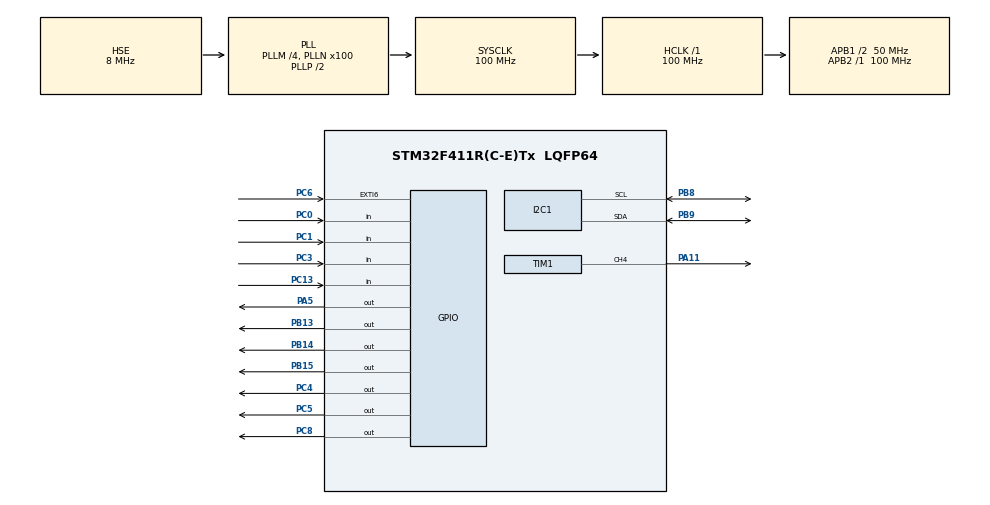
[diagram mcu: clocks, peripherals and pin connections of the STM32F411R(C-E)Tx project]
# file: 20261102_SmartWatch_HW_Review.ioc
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Mcu.Family=STM32F4
Mcu.Name=STM32F411R(C-E)Tx
Mcu.Package=LQFP64
NVIC.EXTI9_5_IRQn=true\:0\:0\:false\:false\:true\:false\:true\:true
NVIC.PriorityGroup=NVIC_PRIORITYGROUP_4
PA11.Signal=S_TIM1_CH4
PA13.Mode=Serial_Wire
PA13.Signal=SYS_JTMS-SWDIO
PA14.Mode=Serial_Wire
PA14.Signal=SYS_JTCK-SWCLK
PA5.Signal=GPIO_Output
PB13.Signal=GPIO_Output
PB14.Signal=GPIO_Output
PB15.Signal=GPIO_Output
PB8.Mode=I2C
PB8.Signal=I2C1_SCL
PB9.Mode=I2C
PB9.Signal=I2C1_SDA
PC0.Signal=GPIO_Input
PC1.Signal=GPIO_Input
PC13-ANTI_TAMP.Signal=GPIO_Input
PC3.Signal=GPIO_Input
PC4.Signal=GPIO_Output
PC5.Signal=GPIO_Output
PC6.GPIO_ModeDefaultEXTI=GPIO_MODE_IT_RISING_FALLING
PC6.Signal=GPXTI6
PC8.Signal=GPIO_Output
PH0\ -\ OSC_IN.Mode=HSE-External-Oscillator
PH0\ -\ OSC_IN.Signal=RCC_OSC_IN
PH1\ -\ OSC_OUT.Mode=HSE-External-Oscillator
PH1\ -\ OSC_OUT.Signal=RCC_OSC_OUT
ProjectManager.HeapSize=0x200
ProjectManager.StackSize=0x400
ProjectManager.TargetToolchain=STM32CubeIDE
RCC.48MHZClocksFreq_Value=50000000
RCC.AHBFreq_Value=100000000
RCC.APB1CLKDivider=RCC_HCLK_DIV2
RCC.APB1Freq_Value=50000000
RCC.APB1TimFreq_Value=100000000
RCC.APB2Freq_Value=100000000
RCC.APB2TimFreq_Value=100000000
RCC.CortexFreq_Value=100000000
RCC.HCLKFreq_Value=100000000
RCC.HSE_VALUE=8000000
RCC.HSI_VALUE=16000000
RCC.LSE_VALUE=32768
RCC.PLLM=4
RCC.PLLN=100
RCC.PLLSourceVirtual=RCC_PLLSOURCE_HSE
RCC.SYSCLKFreq_VALUE=100000000
RCC.SYSCLKSource=RCC_SYSCLKSOURCE_PLLCLK
RCC.VCOOutputFreq_Value=200000000
SH.S_TIM1_CH4.0=TIM1_CH4,PWM Generation4 CH4
TIM1.AutoReloadPreload=TIM_AUTORELOAD_PRELOAD_ENABLE
TIM1.Channel-PWM\ Generation4\ CH4=TIM_CHANNEL_4
TIM1.Prescaler=100-1
VP_TIM1_VS_ClockSourceINT.Mode=Internal
board=custom

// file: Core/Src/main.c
/* USER CODE BEGIN Header */
/**
 ******************************************************************************
 * @file           : main.c
 * @brief          : Main program body
 ******************************************************************************
 * @attention
 *
 * Copyright (c) 2026 STMicroelectronics.
 * All rights reserved.
 *
 * This software is licensed under terms that can be found in the LICENSE file
 * in the root directory of this software component.
 * If no LICENSE file comes with this software, it is provided AS-IS.
 *
 ******************************************************************************
 */
/* USER CODE END Header */
#include "main.h"

/* USER CODE BEGIN Includes */
#include "ap/ap_main.h"

/* USER CODE END Includes */

I2C_HandleTypeDef hi2c1;

TIM_HandleTypeDef htim1;

void SystemClock_Config(void);
static void MX_GPIO_Init(void);
static void MX_TIM1_Init(void);
static void MX_I2C1_Init(void);

/* USER CODE BEGIN 0 */

//typedef enum {
//	BTN_NORMAL = 0,
//	BTN_ERROR,
//	BTN_ALARM
//} btn_event_t;
//
//#define BTN_EVENT_Q_SIZE	6
//
//btn_event_t btnEventArray[BTN_EVENT_Q_SIZE];
//que_buf_t que_btnEvent;

/* USER CODE END 0 */

int main(void)
{

  /* MCU Configuration--------------------------------------------------------*/

  /* Reset of all peripherals, Initializes the Flash interface and the Systick. */
  HAL_Init();

  /* Configure the system clock */
  SystemClock_Config();

  /* Initialize all configured peripherals */
  MX_GPIO_Init();
  MX_TIM1_Init();
  MX_I2C1_Init();
  /* USER CODE BEGIN 2 */
//
//	button_t btn_normal, btn_error, btn_alarm;
//
//	button_init(&btn_normal, GPIOC, GPIO_PIN_0);
//	button_init(&btn_error, GPIOC, GPIO_PIN_1);
//	button_init(&btn_alarm, GPIOC, GPIO_PIN_3);
//
//	que_buf_init(&que_btnEvent, btnEventArray, sizeof(btn_event_t), BTN_EVENT_Q_SIZE);
//	sound_init();
//	sound_power();
  /* USER CODE END 2 */

  /* Infinite loop */
  /* USER CODE BEGIN WHILE */
//	uint32_t prevTime = 0;
//	btn_event_t btnEvent; // 버튼 event enum 변수

	while (1)
	{
		ap_main();
//
//		if (button_getState(&btn_normal) == ACT_RELEASE) {
//			btnEvent = BTN_NORMAL; // 버튼 event 변수에 event 내용 저장
//			que_put(&que_btnEvent, &btnEvent); // que buffer에 event 내용 저장
//		}
//		if (button_getState(&btn_error) == ACT_RELEASE) {
//			btnEvent = BTN_ERROR;
//			que_put(&que_btnEvent, &btnEvent);
//		}
//		if (button_getState(&btn_alarm) == ACT_RELEASE) {
//			btnEvent = BTN_ALARM;
//			que_put(&que_btnEvent, &btnEvent);
//		}
//
//
//		if (HAL_GetTick() - prevTime >= 2000) {
//			prevTime = HAL_GetTick();
//
//			if (!que_is_empty(&que_btnEvent)) {
//
//				que_get(&que_btnEvent, &btnEvent);
//
//				if (btnEvent == BTN_NORMAL) {
//					sound_button();
//				}
//				if (btnEvent == BTN_ERROR) {
//					sound_error();
//				}
//				if (btnEvent == BTN_ALARM) {
//					sound_alarm();
//				}
//			}
//		}

    /* USER CODE END WHILE */

	}
}

void SystemClock_Config(void)
{
  RCC_OscInitTypeDef RCC_OscInitStruct = {0};
  RCC_ClkInitTypeDef RCC_ClkInitStruct = {0};

  /** Configure the main internal regulator output voltage
  */
  __HAL_RCC_PWR_CLK_ENABLE();
  __HAL_PWR_VOLTAGESCALING_CONFIG(PWR_REGULATOR_VOLTAGE_SCALE1);

  /** Initializes the RCC Oscillators according to the specified parameters
  * in the RCC_OscInitTypeDef structure.
  */
  RCC_OscInitStruct.OscillatorType = RCC_OSCILLATORTYPE_HSE;
  RCC_OscInitStruct.HSEState = RCC_HSE_ON;
  RCC_OscInitStruct.PLL.PLLState = RCC_PLL_ON;
  RCC_OscInitStruct.PLL.PLLSource = RCC_PLLSOURCE_HSE;
  RCC_OscInitStruct.PLL.PLLM = 4;
  RCC_OscInitStruct.PLL.PLLN = 100;
  RCC_OscInitStruct.PLL.PLLP = RCC_PLLP_DIV2;
  RCC_OscInitStruct.PLL.PLLQ = 4;
  if (HAL_RCC_OscConfig(&RCC_OscInitStruct) != HAL_OK)
  {
    Error_Handler();
  }

  /** Initializes the CPU, AHB and APB buses clocks
  */
  RCC_ClkInitStruct.ClockType = RCC_CLOCKTYPE_HCLK|RCC_CLOCKTYPE_SYSCLK
                              |RCC_CLOCKTYPE_PCLK1|RCC_CLOCKTYPE_PCLK2;
  RCC_ClkInitStruct.SYSCLKSource = RCC_SYSCLKSOURCE_PLLCLK;
  RCC_ClkInitStruct.AHBCLKDivider = RCC_SYSCLK_DIV1;
  RCC_ClkInitStruct.APB1CLKDivider = RCC_HCLK_DIV2;
  RCC_ClkInitStruct.APB2CLKDivider = RCC_HCLK_DIV1;

  if (HAL_RCC_ClockConfig(&RCC_ClkInitStruct, FLASH_LATENCY_3) != HAL_OK)
  {
    Error_Handler();
  }
}

static void MX_I2C1_Init(void)
{

  hi2c1.Instance = I2C1;
  hi2c1.Init.ClockSpeed = 100000;
  hi2c1.Init.DutyCycle = I2C_DUTYCYCLE_2;
  hi2c1.Init.OwnAddress1 = 0;
  hi2c1.Init.AddressingMode = I2C_ADDRESSINGMODE_7BIT;
  hi2c1.Init.DualAddressMode = I2C_DUALADDRESS_DISABLE;
  hi2c1.Init.OwnAddress2 = 0;
  hi2c1.Init.GeneralCallMode = I2C_GENERALCALL_DISABLE;
  hi2c1.Init.NoStretchMode = I2C_NOSTRETCH_DISABLE;
  if (HAL_I2C_Init(&hi2c1) != HAL_OK)
  {
    Error_Handler();
  }

}

static void MX_TIM1_Init(void)
{

  TIM_ClockConfigTypeDef sClockSourceConfig = {0};
  TIM_MasterConfigTypeDef sMasterConfig = {0};
  TIM_OC_InitTypeDef sConfigOC = {0};
  TIM_BreakDeadTimeConfigTypeDef sBreakDeadTimeConfig = {0};

  htim1.Instance = TIM1;
  htim1.Init.Prescaler = 100-1;
  htim1.Init.CounterMode = TIM_COUNTERMODE_UP;
  htim1.Init.Period = 65535;
  htim1.Init.ClockDivision = TIM_CLOCKDIVISION_DIV1;
  htim1.Init.RepetitionCounter = 0;
  htim1.Init.AutoReloadPreload = TIM_AUTORELOAD_PRELOAD_ENABLE;
  if (HAL_TIM_Base_Init(&htim1) != HAL_OK)
  {
    Error_Handler();
  }
  sClockSourceConfig.ClockSource = TIM_CLOCKSOURCE_INTERNAL;
  if (HAL_TIM_ConfigClockSource(&htim1, &sClockSourceConfig) != HAL_OK)
  {
    Error_Handler();
  }
  if (HAL_TIM_PWM_Init(&htim1) != HAL_OK)
  {
    Error_Handler();
  }
  sMasterConfig.MasterOutputTrigger = TIM_TRGO_RESET;
  sMasterConfig.MasterSlaveMode = TIM_MASTERSLAVEMODE_DISABLE;
  if (HAL_TIMEx_MasterConfigSynchronization(&htim1, &sMasterConfig) != HAL_OK)
  {
    Error_Handler();
  }
  sConfigOC.OCMode = TIM_OCMODE_PWM1;
  sConfigOC.Pulse = 0;
  sConfigOC.OCPolarity = TIM_OCPOLARITY_HIGH;
  sConfigOC.OCFastMode = TIM_OCFAST_DISABLE;
  sConfigOC.OCIdleState = TIM_OCIDLESTATE_RESET;
  sConfigOC.OCNIdleState = TIM_OCNIDLESTATE_RESET;
  if (HAL_TIM_PWM_ConfigChannel(&htim1, &sConfigOC, TIM_CHANNEL_4) != HAL_OK)
  {
    Error_Handler();
  }
  sBreakDeadTimeConfig.OffStateRunMode = TIM_OSSR_DISABLE;
  sBreakDeadTimeConfig.OffStateIDLEMode = TIM_OSSI_DISABLE;
  sBreakDeadTimeConfig.LockLevel = TIM_LOCKLEVEL_OFF;
  sBreakDeadTimeConfig.DeadTime = 0;
  sBreakDeadTimeConfig.BreakState = TIM_BREAK_DISABLE;
  sBreakDeadTimeConfig.BreakPolarity = TIM_BREAKPOLARITY_HIGH;
  sBreakDeadTimeConfig.AutomaticOutput = TIM_AUTOMATICOUTPUT_DISABLE;
  if (HAL_TIMEx_ConfigBreakDeadTime(&htim1, &sBreakDeadTimeConfig) != HAL_OK)
  {
    Error_Handler();
  }
  HAL_TIM_MspPostInit(&htim1);

}

static void MX_GPIO_Init(void)
{
  GPIO_InitTypeDef GPIO_InitStruct = {0};

  /* GPIO Ports Clock Enable */
  __HAL_RCC_GPIOC_CLK_ENABLE();
  __HAL_RCC_GPIOH_CLK_ENABLE();
  __HAL_RCC_GPIOA_CLK_ENABLE();
  __HAL_RCC_GPIOB_CLK_ENABLE();

  /*Configure GPIO pin Output Level */
  HAL_GPIO_WritePin(GPIOA, GPIO_PIN_5, GPIO_PIN_RESET);

  /*Configure GPIO pin Output Level */
  HAL_GPIO_WritePin(GPIOC, GPIO_PIN_4|GPIO_PIN_5|GPIO_PIN_8, GPIO_PIN_RESET);

  /*Configure GPIO pin Output Level */
  HAL_GPIO_WritePin(GPIOB, GPIO_PIN_13|GPIO_PIN_14|GPIO_PIN_15, GPIO_PIN_RESET);

  /*Configure GPIO pins : PC13 PC0 PC1 PC3 */
  GPIO_InitStruct.Pin = GPIO_PIN_13|GPIO_PIN_0|GPIO_PIN_1|GPIO_PIN_3;
  GPIO_InitStruct.Mode = GPIO_MODE_INPUT;
  GPIO_InitStruct.Pull = GPIO_NOPULL;
  HAL_GPIO_Init(GPIOC, &GPIO_InitStruct);

  /*Configure GPIO pin : PA5 */
  GPIO_InitStruct.Pin = GPIO_PIN_5;
  GPIO_InitStruct.Mode = GPIO_MODE_OUTPUT_PP;
  GPIO_InitStruct.Pull = GPIO_NOPULL;
  GPIO_InitStruct.Speed = GPIO_SPEED_FREQ_LOW;
  HAL_GPIO_Init(GPIOA, &GPIO_InitStruct);

  /*Configure GPIO pins : PC4 PC5 PC8 */
  GPIO_InitStruct.Pin = GPIO_PIN_4|GPIO_PIN_5|GPIO_PIN_8;
  GPIO_InitStruct.Mode = GPIO_MODE_OUTPUT_PP;
  GPIO_InitStruct.Pull = GPIO_NOPULL;
  GPIO_InitStruct.Speed = GPIO_SPEED_FREQ_LOW;
  HAL_GPIO_Init(GPIOC, &GPIO_InitStruct);

  /*Configure GPIO pins : PB13 PB14 PB15 */
  GPIO_InitStruct.Pin = GPIO_PIN_13|GPIO_PIN_14|GPIO_PIN_15;
  GPIO_InitStruct.Mode = GPIO_MODE_OUTPUT_PP;
  GPIO_InitStruct.Pull = GPIO_NOPULL;
  GPIO_InitStruct.Speed = GPIO_SPEED_FREQ_LOW;
  HAL_GPIO_Init(GPIOB, &GPIO_InitStruct);

  /*Configure GPIO pin : PC6 */
  GPIO_InitStruct.Pin = GPIO_PIN_6;
  GPIO_InitStruct.Mode = GPIO_MODE_IT_RISING_FALLING;
  GPIO_InitStruct.Pull = GPIO_NOPULL;
  HAL_GPIO_Init(GPIOC, &GPIO_InitStruct);

  /* EXTI interrupt init*/
  HAL_NVIC_SetPriority(EXTI9_5_IRQn, 0, 0);
  HAL_NVIC_EnableIRQ(EXTI9_5_IRQn);

  /* USER CODE BEGIN MX_GPIO_Init_2 */
  HAL_NVIC_DisableIRQ(EXTI9_5_IRQn);
  GPIO_InitStruct.Pin = GPIO_PIN_13;
  GPIO_InitStruct.Mode = GPIO_MODE_INPUT;
  GPIO_InitStruct.Pull = GPIO_NOPULL;
  HAL_GPIO_Init(GPIOC, &GPIO_InitStruct);

  /* USER CODE END MX_GPIO_Init_2 */
}

void Error_Handler(void)
{
	__disable_irq();
	while (1)
	{
	}
}
